# AC690N register map
Vendor: JieLi; Series: BR17; File version: 1.0
CPU: PI32 r1, little endian, no MPU, no FPU, 2 interrupt priority bits, 64 interrupts
Registers are 32-bit, read-write, reset 0x0 unless marked. A register's access mark holds for its fields unless they carry their own. Offsets are from the block's base; [hi:lo] are bit positions; {n}, {i} and the like mark numbered series.

## SPI0 — Serial Peripheral Interface controller
Base 0x00060400
Same registers: SPI1 0x00060414, SPI2 0x00060428
0x00 CON 16-bit — Control register
0x04 BAUD 16-bit — Clock divider register
0x08 BUF 8-bit — Data buffer
0x0C ADR wo — DMA buffer base address
0x10 CNT 16-bit wo — DMA transfer byte count

## PAP — Parralel Active Port
Base 0x00060500
0x00 CON 16-bit — Control register
0x04 DAT0 16-bit — Data register 0
0x08 DAT1 16-bit — Data register 1
0x10 ADR wo — DMA buffer base address
0x14 CNT 16-bit wo — DMA transfer byte count

## SD0 — SD/MMC host
Base 0x00060600
Same registers: SD1 0x00060614
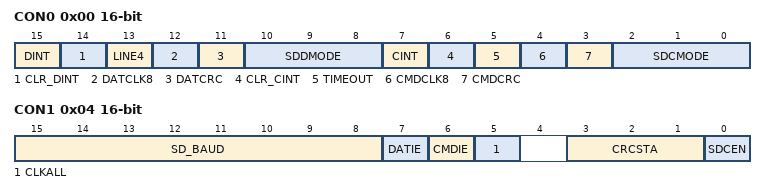
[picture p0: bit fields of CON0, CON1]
0x00 CON0 16-bit — Control register 0
  [15] DINT ro — Data interrupt status
  [14] CLR_DINT wo — Writing '1' clears a pending data interrupt
  [13] LINE4 — Data bus width
    0=1-bit bus width (DAT0); 1=4-bit bus width (DAT0-3)
  [12] DATCLK8 — Data clock stretch by 8 clocks?
  [11] DATCRC ro — Data CRC error flag
  [10:8] SDDMODE — Data transfer mode
    0=nop (No operation); 5=Send data to card; 6=Receive data from card
  [7] CINT ro — Command interrupt status
  [6] CLR_CINT wo — Writing '1' clears a pending command interrupt
  [5] TIMEOUT ro — Command response timeout flag
  [4] CMDCLK8 — Sends 8 clocks at somewhere in command phase?
  [3] CMDCRC ro — Command CRC error status
  [2:0] SDCMODE wo — Command transfer mode
    0=nop (No operation); 1=resp48_busy (48-bit response, checks busy signal); 2=resp136_busy (136-bit response, checks busy signal); 3=noresp_busy (No response, checks busy signal); 5=resp48_nobusy (48-bit response, does not check busy signal); 6=resp136_nobusy (136-bit response, does not check busy signal); 7=noresp_nobusy (No response, does not check busy signal)
0x04 CON1 16-bit — Control register 1
  [15:8] SD_BAUD — Card clock divider, Fcard = Fbus / (N + 1)
  [7] DATIE — Enable data interrupt
  [6] CMDIE — Enable command interrupt
  [5] CLKALL — Always output card clock
  [3:1] CRCSTA ro — CRC status bits
  [0] SDCEN — Controller enable
0x08 CON2 16-bit reset 0x200 — Control register 2
  [8:0] SDDCNT — Data block size, blksz = [SDDCNT] + 1
0x0C CPTR 16-bit — Command buffer address
0x10 DPTR 16-bit — Data buffer address

## LSMISC — Misc stuff on lowspeed bus
Base 0x00060900
0x00 PWM4_CON 16-bit — 4th PWM channel (?) control register
0x04 IRTC_CON 16-bit — IRTC control register
0x08 IRFLT_CON 16-bit — IR filter control register

## AUDIO — Audio codec
Base 0x00060A00
0x00 DAC_LEN 16-bit wo — DAC buffer length
0x04 DAC_CON 16-bit — DAC control register
0x08 DAC_ADR wo — DAC buffer address
0x0C DAC_TRML 8-bit wo — DAC left channel trim
0x10 DAC_TRMR 8-bit wo — DAC right channel trim
0x20 LADC_CON 16-bit — LADC control register
0x2C LADC_ADR wo — LADC buffer address
0x30 LADC_LEN 16-bit wo — LADC buffer length
{0x40+4i} DAA_CON{i} 16-bit (i=0..3) — D-A analog control register {i}
0x50 DAA_CON4 8-bit — D-A analog control register 2
0x54 DAA_CON5 8-bit — D-A analog control register 5
{0x80+4i} ADA_CON{i} 16-bit (i=0..2) — A-D analog control register {i}

## ALNK — Serial audio link (I2S)
Base 0x00060B00
{0x0+4i} CON{i} 16-bit (i=0..2) — Control register {i}
{0xC+4i} ADR{i} wo (i=0..3) — DAT{i} buffer base address
0x1C LEN 16-bit wo — Buffer length

## NFC — ISO-14993 NFC
Base 0x00060C00
{0x4+4i} CON{i} (i=0..2) — Control register {i}
0x10 BUF0 — Data buffer 0
0x14 BUF1 — Data buffer 1
0x18 BUF2 wo — Data buffer 2
0x1C BUF3 wo — Data buffer 3

## USB — Full-speed dual role USB controller
Base 0x00060D00
0x00 IO_CON 16-bit — USB IO port control
0x04 CON0 16-bit — USB control register 0
0x08 CON1 16-bit — USB control register 1
{0xC+4i} EP{i}_CNT 16-bit wo (i=0..3) — USB endpoint {i} TX byte count
0x1C EP0_ADR wo — USB endpoint 0 buffer base address
{0x18+8i} EP{i}_TADR wo (i=1..3) — USB endpoint {i} TX buffer base address
{0x1C+8i} EP{i}_RADR wo (i=1..3) — USB endpoint {i} RX buffer base address

## CRC — CRC16-CCITT
Base 0x00060E00
0x00 FIFO 8-bit wo — Data input FIFO(?)
0x04 REG 16-bit — CRC register (writing 0x6EA5 unlocks some stuff like MODE_CON or WDT_CON!)

## RAND — 64-bit random number generator
Base 0x00060F00
0x00 R64L ro — Low 32-bits of the random result
0x04 R64H ro — High 32-bits of the random result

## ADC — Generic 10-bit ADC
Base 0x00061000
0x00 CON 16-bit — Control register 0
0x04 RES 16-bit ro — Conversion result

## PLCNT — Pulse counter
Base 0x00061100
0x00 CON 8-bit — Control register
0x04 VL 16-bit — Count value

## PD — Power down control
Base 0x00061200
0x00 CON 16-bit — Control register
0x04 DAT 8-bit — Data buffer

## CTM — Charge time measurement unit
Base 0x00061300
0x00 CON0 16-bit — Control register 0
0x04 CON1 — Control register 1
0x08 RES 16-bit ro — Result register

## CPU — CPU or like peripherals
Base 0x00070000
0x00 DSP_CON — DSP control register
{0x4+0xC*i} ILAT{i} (i=0..1) ro — Interrupt latch status
{0x8+0xC*i} ILAT{i}_SET (i=0..1) wo — Interrupt latch set bits
{0xC+0xC*i} ILAT{i}_CLR (i=0..1) wo — Interrupt latch clear bits
{0x1C+4i} IPCON{i} (i=0..3) — Interrupt priority control
0x40 TICK_CON 8-bit — Tick timer control register
0x44 TICK_CNT — Tick timer counter
0x48 TICK_PRD — Tick timer period

## DEBUG — Debug-ish stuff
Base 0x00070100
0x00 DSP_BF_CON — wa
0x04 WR_EN — wa
0x08 MSG ro — Debug message bits
0x0C MSG_CLR — Debug message bits clear
0x10 DSP_PC_LIMH — DSP program counter limit high
0x14 DSP_PC_LIML — DSP program counter limit low
0x18 DSP_EX_LIMH — DSP ex(?) limit high
0x1C DSP_EX_LIML — DSP ex(?) limit low
0x20 PRP_EX_LIMH — PRP ex(?) limit high
0x24 PRP_EX_LIML — PRP ex(?) limit low
0x28 PRP_MMU_MSG ro — wa
0x2C LSB_MMU_MSG_CH ro — wa
0x30 PRP_WR_LIMIT_MSG ro — wa
0x34 LSB_WR_LIMIT_CH ro — wa

## SFC — Serial flash controller
Base 0x00070200
0x00 CON — Control register
0x04 BAUD 8-bit wo — Clock divider register
0x08 CODE 16-bit wo — wa
0x0C BASE_ADR wo — Flash base address register

## ENC — Enc-rypter
Base 0x00070300
0x00 CON 8-bit — Control register
0x04 KEY 16-bit wo
0x08 ADR 16-bit wo
0x0C UNENC_ADRH — Unencrypted address range (high)
0x10 UNENC_ADRL — Unencrypted address range (low)

## AES — AES engine
Base 0x00070500
0x00 CON — Control register
0x04 DATIN — Input data register
0x08 KEY wo
{0xC+4i} ENCRES{i} (i=0..3) — Encrypted result
{0x1C+4i} DECRES{i} (i=0..3) — Decrypted result

## FFT — Fast Fourier transform
Base 0x00070600
0x00 CON — Control register
0x04 ADRI — Input buffer base address
0x08 ADRO — Output buffer base address
0x0C ADRW — Window data base address

## EQ — Equalizer
Base 0x00070700
0x00 CON — Control register
0x04 LEN — Buffer length
0x08 ADRI — Input buffer base address
0x0C ADRO — Output buffer base address
0x10 CADR — Coefficent(?) base address

## SRC — Sampling rate converter
Base 0x00070800
{0x0+4i} CON{i} (i=0..3) — Control register {i}
0x10 IDAT_ADR — Input data buffer base address
0x14 IDAT_LEN — Input data length
0x18 ODAT_ADR — Output data buffer base address
0x1C ODAT_LEN — Output data length
0x20 FLTB_ADR — FLTB base address
